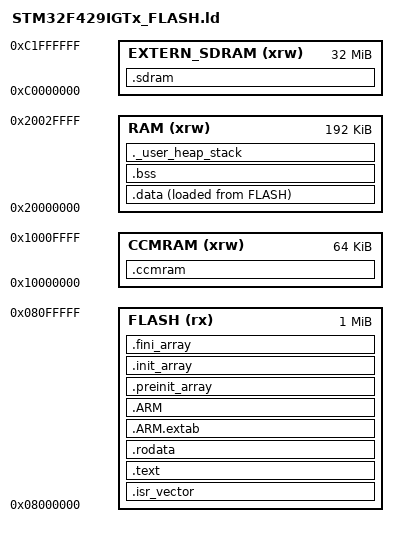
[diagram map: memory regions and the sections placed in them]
/*
******************************************************************************
**
**  File        : STM32F429IGTx_FLASH.ld
**
**  Abstract    : Linker script for STM32F429IGTx Device with
**                1024KByte FLASH, 192KByte RAM (internal)
**
**                Set heap size, stack size and stack location according
**                to application requirements.
**
**                Set memory bank area and size if external memory is used.
**
**  Target      : STM32F429IGTx (阿波罗开发板)
**
**  Distribution: This file is distributed "as is", without any warranty
**                of any kind.
**
*****************************************************************************
*/

/* Entry Point */
ENTRY(Reset_Handler)

/* Highest address of the user mode stack */
_estack = ORIGIN(RAM) + LENGTH(RAM);    /* end of RAM */

/* Generate a link error if heap and stack don't fit into RAM */
_Min_Heap_Size = 0x1000;     /* bounded newlib heap; independent of FreeRTOS heap_4 */
_Min_Stack_Size = 0x1000;    /* minimum reserved main/interrupt stack */

/* Specify the memory areas */
MEMORY
{
  RAM (xrw)     : ORIGIN = 0x20000000, LENGTH = 192K
  CCMRAM (xrw)  : ORIGIN = 0x10000000, LENGTH = 64K
  EXTERN_SDRAM (xrw) : ORIGIN = 0xC0000000, LENGTH = 32M
  FLASH (rx)    : ORIGIN = 0x08000000, LENGTH = 1024K
}

/* Define output sections */
SECTIONS
{
  /* The startup code goes first into FLASH */
  .isr_vector :
  {
    . = ALIGN(4);
    KEEP(*(.isr_vector)) /* Startup code */
    . = ALIGN(4);
  } >FLASH

  /* The program code and other data goes into FLASH */
  .text :
  {
    . = ALIGN(4);
    *(.text)           /* .text sections (code) */
    *(.text*)          /* .text* sections (code) */
    *(.glue_7)         /* glue arm to thumb code */
    *(.glue_7t)        /* glue thumb to arm code */
    *(.eh_frame)

    KEEP (*(.init))
    KEEP (*(.fini))

    . = ALIGN(4);
    _etext = .;        /* define a global symbols at end of code */
  } >FLASH

  /* Constant data goes into FLASH */
  .rodata :
  {
    . = ALIGN(4);
    *(.rodata)         /* .rodata sections (constants, strings, etc.) */
    *(.rodata*)        /* .rodata* sections (constants, strings, etc.) */
    . = ALIGN(4);
  } >FLASH

  .ARM.extab   : { *(.ARM.extab* .gnu.linkonce.armextab.*) } >FLASH
  .ARM : {
    __exidx_start = .;
    *(.ARM.exidx*)
    __exidx_end = .;
  } >FLASH

  .preinit_array     :
  {
    PROVIDE_HIDDEN (__preinit_array_start = .);
    KEEP (*(.preinit_array*))
    PROVIDE_HIDDEN (__preinit_array_end = .);
  } >FLASH

  .init_array :
  {
    PROVIDE_HIDDEN (__init_array_start = .);
    KEEP (*(SORT(.init_array.*)))
    KEEP (*(.init_array*))
    PROVIDE_HIDDEN (__init_array_end = .);
  } >FLASH

  .fini_array :
  {
    PROVIDE_HIDDEN (__fini_array_start = .);
    KEEP (*(SORT(.fini_array.*)))
    KEEP (*(.fini_array*))
    PROVIDE_HIDDEN (__fini_array_end = .);
  } >FLASH

  /* used by the startup to initialize data */
  _sidata = LOADADDR(.data);

  /* Initialized data sections goes into RAM, load LMA copy after code */
  .data :
  {
    . = ALIGN(4);
    _sdata = .;        /* create a global symbol at data start */
    *(.data)           /* .data sections */
    *(.data*)          /* .data* sections */
    *(.RamFunc)        /* .RamFunc sections */
    *(.RamFunc*)       /* .RamFunc* sections */

    . = ALIGN(4);
    _edata = .;        /* define a global symbol at data end */
  } >RAM AT> FLASH

  /* Uninitialized data section */
  . = ALIGN(4);
  .bss :
  {
    /* This is used by the startup in order to initialize the .bss section */
    _sbss = .;         /* define a global symbol at bss start */
    __bss_start__ = _sbss;
    *(.bss)
    *(.bss*)
    *(COMMON)

    . = ALIGN(4);
    _ebss = .;         /* define a global symbol at bss end */
    __bss_end__ = _ebss;
  } >RAM

  /* User_heap_stack section, used to check that there is enough RAM left */
  ._user_heap_stack :
  {
    . = ALIGN(8);
    PROVIDE ( end = . );
    PROVIDE ( _end = . );
    __HeapBase = .;
    . = . + _Min_Heap_Size;
    __HeapLimit = .;
    . = . + _Min_Stack_Size;
    . = ALIGN(8);
  } >RAM

  __StackLimit = _estack - _Min_Stack_Size;
  ASSERT(__HeapLimit <= __StackLimit, "RAM overflow: heap and main stack overlap")

  /* CCMRAM section — explicitly placed variables for CPU-only SRAM */
  .ccmram (NOLOAD) :
  {
    . = ALIGN(4);
    *(.ccmram)
    *(.ccmram*)
    . = ALIGN(4);
  } >CCMRAM

  /* External SDRAM section — frame buffer + malloc pool (Apollo board 32MB SDRAM) */
  .sdram (NOLOAD) :
  {
    . = ALIGN(4);
    *(.sdram)
    *(.sdram*)
    . = ALIGN(4);
  } >EXTERN_SDRAM

  /* Remove information from the standard libraries */
  /DISCARD/ :
  {
    libc.a ( * )
    libm.a ( * )
    libgcc.a ( * )
  }

  .ARM.attributes 0 : { *(.ARM.attributes) }
}
